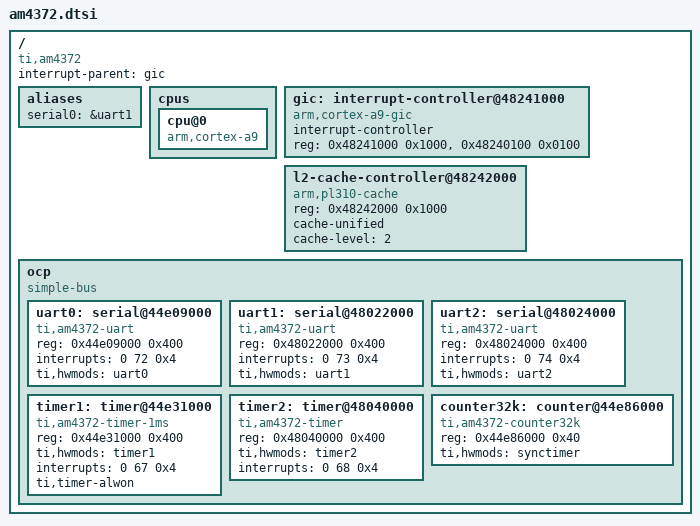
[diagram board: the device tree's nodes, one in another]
/*
 * Device Tree Source for AM4372 SoC
 *
 * Copyright (C) 2013 Texas Instruments Incorporated - http://www.ti.com/
 *
 * This file is licensed under the terms of the GNU General Public License
 * version 2.  This program is licensed "as is" without any warranty of any
 * kind, whether express or implied.
 */

/include/ "skeleton.dtsi"

/ {
	compatible = "ti,am4372", "ti,am43";
	interrupt-parent = <&gic>;


	aliases {
		serial0 = &uart1;
	};

	cpus {
		cpu@0 {
			compatible = "arm,cortex-a9";
		};
	};

	gic: interrupt-controller@48241000 {
		compatible = "arm,cortex-a9-gic";
		interrupt-controller;
		#interrupt-cells = <3>;
		reg = <0x48241000 0x1000>,
		      <0x48240100 0x0100>;
	};

	l2-cache-controller@48242000 {
		compatible = "arm,pl310-cache";
		reg = <0x48242000 0x1000>;
		cache-unified;
		cache-level = <2>;
	};

	ocp {
		compatible = "simple-bus";
		#address-cells = <1>;
		#size-cells = <1>;
		ranges;
		
		uart0: serial@44e09000 {
			compatible = "ti,am4372-uart","ti,omap4-uart";
			reg = <0x44e09000 0x400>;
			interrupts = <0 72 0x4>;
			ti,hwmods = "uart0";
		};

		uart1: serial@48022000 {
			compatible = "ti,am4372-uart","ti,omap4-uart";
			reg = <0x48022000 0x400>;
			interrupts = <0 73 0x4>;
			ti,hwmods = "uart1";
		};

		uart2: serial@48024000 {
			compatible = "ti,am4372-uart","ti,omap4-uart";
			reg = <0x48024000 0x400>;
			interrupts = <0 74 0x4>;
			ti,hwmods = "uart2";
		};

		timer1: timer@44e31000 {
			compatible = "ti,am4372-timer-1ms","ti,am335x-timer-1ms";
			reg = <0x44e31000 0x400>;
			ti,hwmods = "timer1";
			interrupts = <0 67 0x4>;
			ti,timer-alwon;
		};

		timer2: timer@48040000  {
			compatible = "ti,am4372-timer","ti,am335x-timer";
			reg = <0x48040000  0x400>;
			ti,hwmods = "timer2";
			interrupts = <0 68 0x4>;
		};

		counter32k: counter@44e86000 {
			compatible = "ti,am4372-counter32k","ti,omap-counter32k";
			reg = <0x44e86000 0x40>;
			ti,hwmods = "synctimer";
		};
	};
};
